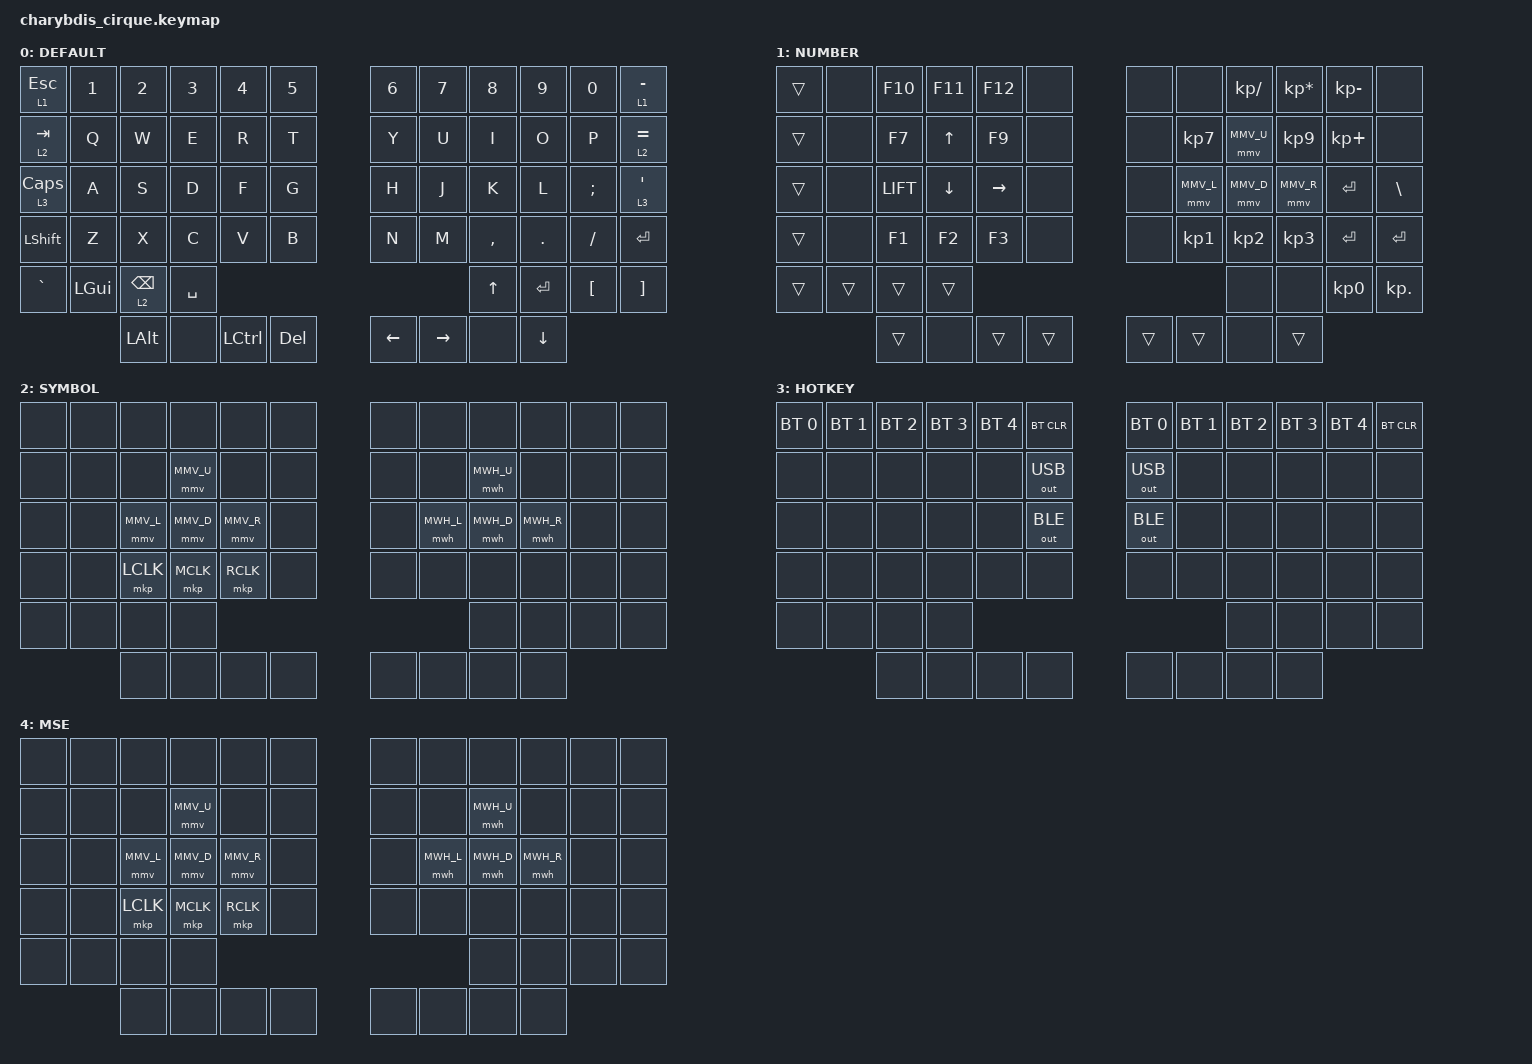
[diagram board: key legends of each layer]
#include <behaviors.dtsi>
#include <dt-bindings/zmk/mouse.h>
#include <dt-bindings/zmk/keys.h>
#include <dt-bindings/zmk/bt.h>
#include <dt-bindings/zmk/outputs.h>

// mouse move settings
#define MMV_U MOVE_VERT(-650)
#define MMV_D MOVE_VERT(650)
#define MMV_L MOVE_HOR(-650)
#define MMV_R MOVE_HOR(650)

&mmv {    
        time-to-max-speed-ms = <500>;
        acceleration-exponent=<1>;
};

// mouse wheel settings
#define MWH_U SCROLL_VERT(15)
#define MWH_D SCROLL_VERT(-15)
#define MWH_L SCROLL_HOR(-15)
#define MWH_R SCROLL_HOR(15)

&mwh {    
        time-to-max-speed-ms = <2000>;
        acceleration-exponent=<0>;
};

#define DEFAULT 0
#define NUMBER  1
#define SYMBOL  2
#define HOTKEY  3
#define MSE     4

#define AS(keycode) &as LS(keycode) keycode

/ {
        behaviors {
        td0: tap_dance_0 {
            compatible = "zmk,behavior-tap-dance";
            label = "TAP_DANCE_0";
            #binding-cells = <0>;
            tapping-term-ms = <200>;
            bindings = <&kp ESC>, <&kp TAB>;
        };
    };  

         behaviors {
       as: auto_shift {
        compatible = "zmk,behavior-hold-tap";
        label = "AUTO_SHIFT";
        #binding-cells = <2>;
        tapping-term-ms = <200>;
        quick-tap-ms = <0>;
        flavor = "tap-preferred";
        bindings = <&kp>, <&kp>;
                };             
modcp: mod_copy {
        compatible = "zmk,behavior-mod-morph";
        label = "MOD_COPY";
        #binding-cells = <0>;
        bindings = <&as LS(C) C>, <&kp C>;
        mods = <(LGUI | RGUI)>;
};
        };


    macros {
        macro_phone: macro_phone {
            // 1351
            label = "MACRO_PHONE";
            compatible = "zmk,behavior-macro";
            #binding-cells = <0>;
            bindings
                = < &kp N1 &kp N3 &kp N5  &kp N1>
                ;
        };
        macro_email_q: macro_email_q {
            // 2894512440@qq.com
            label = "MACRO_EMAIL_QQ";
            compatible = "zmk,behavior-macro";
            #binding-cells = <0>;
            bindings 
                = < &kp N2 &kp N8 &kp N9 &kp N4 &kp N5 &kp  N1 &kp N2 &kp N4 &kp N4 &kp N0 
                    &kp AT &kp Q &kp Q &kp DOT  &kp C &kp O &kp M>
                ;
        };
        macro_email_g: macro_email_g {
            // 135115
            compatible = "zmk,behavior-macro";
            label = "MACRO_EMAIL_GMAIL";
            #binding-cells = <0>;
            bindings
                = < &kp N1 &kp N3 &kp N5  &kp N1 &kp N1 &kp N5 > ;
        };
       
    };
    




    keymap {
       compatible = "zmk,keymap";
       default_layer {
            label = "DEFAULT";
            bindings = <
&lt 1 ESC &kp N1 &kp N2 &kp N3 &kp N4 &kp N5           &kp N6  &kp N7  &kp N8  &kp N9  &kp N0   &lt 1  MINUS
&lt 2 TAB    &kp Q  &kp W    &kp E   &kp R   &kp T        &kp Y  &kp U     &kp I     &kp O    &kp P    &lt 2 EQUAL
&lt 3 CAPS  &kp A  &kp S    &kp D    &kp F     &kp G               &kp H  &kp J     &kp K     &kp L    &kp SEMI &lt 3 SQT
&kp LSHFT &kp Z  &kp X    &kp C    &kp V     &kp B                &kp N  &kp M     &kp COMMA &kp DOT  &kp FSLH &kp ENTER 
&kp GRAVE  &kp LGUI  &lt 2 BSPC &kp SPACE                    &kp UP &kp ENTER    &kp LBKT  &kp RBKT          
&kp LALT &none	&kp LCTRL 	&kp DEL 	       &kp LEFT   &kp RIGHT &none &kp DOWN    
            >;
        };  


          number_layer {
            label = "NUMBER";
            bindings = <
  &trans  &none &kp F10 &kp F11   &kp F12 &none             &none  &none    &kp KP_SLASH &kp KP_MULTIPLY   &kp KP_MINUS  &none
    &trans  &none &kp F7  &kp UP   &kp F9  &none              &none &kp KP_N7  &mmv MMV_U  &kp KP_N9 &kp KP_PLUS  &none 
    &trans   &none  &kp LIFT   &kp DOWN   &kp RIGHT  &none           &none &mmv MMV_L  &mmv MMV_D  &mmv MMV_R &kp ENTER    &kp BSLH
   &trans  &none  &kp F1    &kp F2    &kp F3    &none           &none &kp KP_N1 &kp KP_N2 &kp KP_N3 &kp ENTER  &kp ENTER 
   &trans     &trans     &trans    &trans                                  &none &none	&kp KP_N0 &kp KP_DOT	
      &trans   &none    &trans    &trans                                       &trans     &trans      &none    &trans     
            >;
        };

        symbol_layer {
            label = "SYMBOL";
            bindings = <
                &none &none &none &none   &none &none &none &none   &none &none &none &none 
 &none &none  &none       &mmv MMV_U  &none       &none       &none  &none       &mwh MWH_U  &none       &none  &none
            &none     &none  &mmv MMV_L  &mmv MMV_D  &mmv MMV_R  &none       &none  &mwh MWH_L  &mwh MWH_D  &mwh MWH_R  &none  &none
&none &none &mkp LCLK &mkp MCLK &mkp RCLK &none                                            &none &none &none &none &none &none
   &none &none &none &none                                                              &none &none &none &none
   &none &none &none &none                                                              &none &none &none &none                                                                                            
         >;
        };


        hotkey_layer {
            label = "HOTKEY";
            bindings = <
 &bt BT_SEL 0 &bt BT_SEL 1 &bt BT_SEL 2 &bt BT_SEL 3 &bt BT_SEL 4 &bt BT_CLR            &bt BT_SEL 0 &bt BT_SEL 1 &bt BT_SEL 2 &bt BT_SEL 3 &bt BT_SEL 4 &bt BT_CLR
&none	&none	&none	&none	&none	&out OUT_USB	&out OUT_USB	&none	&none	&none	&none	&none
&none	&none	&none	&none	&none	&out OUT_BLE	&out OUT_BLE	&none	&none	&none	&none	&none
  &none &none &none &none   &none &none &none &none   &none &none &none &none 
   &none &none &none &none                                                              &none &none &none &none
   &none &none &none &none                                                              &none &none &none &none                                                     
            >;
        };
        
            mouse_layer {
            label = "MSE";
            bindings = <
            
              &none &none &none &none   &none &none &none &none   &none &none &none &none 
 &none &none  &none       &mmv MMV_U  &none       &none       &none  &none       &mwh MWH_U  &none       &none  &none
            &none     &none  &mmv MMV_L  &mmv MMV_D  &mmv MMV_R  &none       &none  &mwh MWH_L  &mwh MWH_D  &mwh MWH_R  &none  &none
&none &none &mkp LCLK &mkp MCLK &mkp RCLK &none                                            &none &none &none &none &none &none
   &none &none &none &none                                                              &none &none &none &none
   &none &none &none &none                                                              &none &none &none &none                                                     
            >;
        };
        
        
        
   };
};
